# ESP32-S31 register map
Vendor: ESPRESSIF SYSTEMS (SHANGHAI) CO., LTD.; Series: ESP32 S-Series; File version: 1
CPU: RV32IMAFC r0p0, little endian, no MPU, FPU, 0 interrupt priority bits
Address unit: 32 bits
Registers are 32-bit, read-write, reset 0x0 unless marked. A register's access mark holds for its fields unless they carry their own. Offsets are from the block's base; [hi:lo] are bit positions; {n}, {i} and the like mark numbered series.

## JPEG — JPEG Codec
Base 0x20344000
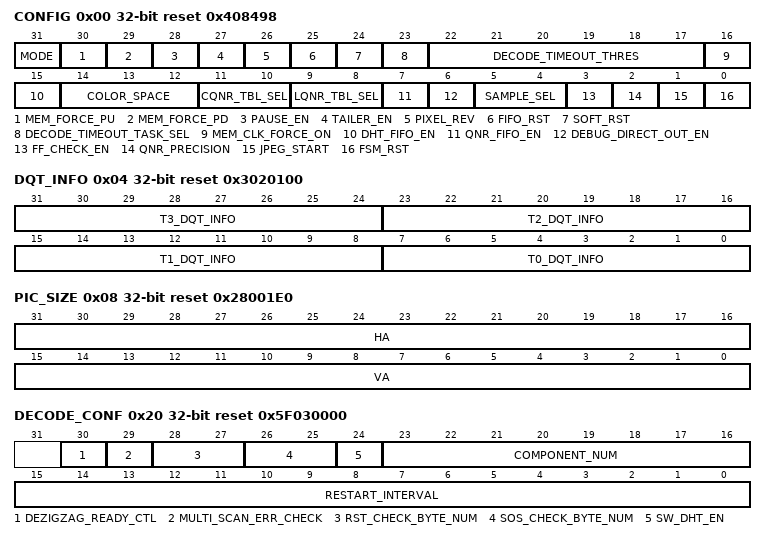
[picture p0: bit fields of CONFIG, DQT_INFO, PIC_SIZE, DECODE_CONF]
0x00 CONFIG access per field reset 0x408498 — Control and configuration registers
  [31] MODE rw — 0:encoder mode, 1: decoder mode
  [30] MEM_FORCE_PU rw — 0: no operation,1:force jpeg memory to power up
  [29] MEM_FORCE_PD rw — 0: no operation,1:force jpeg memory to power down
  [28] PAUSE_EN rw — set this bit to pause jpeg encoding
  [27] TAILER_EN rw — set this bit to add EOI of '0xffd9' at the end of bitstream
  [26] PIXEL_REV rw — reverse the source color pixel
  [25] FIFO_RST rw — fifo reset
  [24] SOFT_RST rw — when set to 1, soft reset JPEG module except jpeg_reg module
  [23] DECODE_TIMEOUT_TASK_SEL rw — 0: software use reset to abort decode process ,1: decoder abort decode process by itself
  [22:17] DECODE_TIMEOUT_THRES rw — decode pause period to trigger decode_timeout int, the timeout periods =2 power (reg_decode_timeout_thres) -1
  [16] MEM_CLK_FORCE_ON rw — force memory's clock enabled
  [15] DHT_FIFO_EN rw — 0:use non-fifo way to write dht len_total/codemin/value table,1:use fifo way to write dht len_total/codemin/value table. Reading dht len_total/codemin/value table only has nonfifo way
  [14:12] COLOR_SPACE rw — configure picture's color space:0-rgb888,1-yuv422,2-rgb565,3-gray,4-yuv444,5-yuv420
  [11:10] CQNR_TBL_SEL rw — choose chrominance quntization table id (TBD)
  [9:8] LQNR_TBL_SEL rw — choose luminance quntization table id(TBD)
  [7] QNR_FIFO_EN rw — 0:use non-fifo way to access qnr ram,1:use fifo way to access qnr ram
  [6] DEBUG_DIRECT_OUT_EN rw — 0:normal mode,1:debug mode for direct output from input
  [5:4] SAMPLE_SEL rw — 0:yuv444,1:yuv422, 2:yuv420
  [3] FF_CHECK_EN rw — enable whether to add '00' after 'ff'
  [2] QNR_PRECISION rw — 0:8bit qnr,1:12bit qnr(TBD)
  [1] JPEG_START wo — start to compress a new pic(in dma reg mode)
  [0] FSM_RST wo — fsm reset
0x04 DQT_INFO reset 0x3020100 — Control and configuration registers
  [8n+7:8n] T{n}_DQT_INFO (n=0..3) — Configure dqt table{n}'s quantization coefficient precision in bit[7:4], configure dqt table{n}'s table id in bit[3:0]
0x08 PIC_SIZE reset 0x28001E0 — Control and configuration registers
  [31:16] HA — configure picture's width. when encode, the max configurable bits is 14, when decode, the max configurable bits is 16
  [15:0] VA — configure picture's height. when encode, the max configurable bits is 14, when decode, the max configurable bits is 16
{0x10+4i} T{i}QNR ro (i=0..3) — Control and configuration registers
  [31:0] T{i}_QNR_VAL — write this reg to configure 64 quantization coefficient in t{i} table
0x20 DECODE_CONF access per field reset 0x5F030000 — Control and configuration registers
  [30] DEZIGZAG_READY_CTL rw — reserved for decoder
  [29] MULTI_SCAN_ERR_CHECK rw — reserved for decoder
  [28:27] RST_CHECK_BYTE_NUM rw — Configure the byte number to check next rst marker after one rst interval is decoded down. The real check number is reg_rst_check_byte_num+1
  [26:25] SOS_CHECK_BYTE_NUM rw — Configure the byte number to check next sos marker in the multi-scan picture after one scan is decoded down. The real check number is reg_sos_check_byte_num+1
  [24] SW_DHT_EN ro — software decode dht table enable
  [23:16] COMPONENT_NUM rw — configure number of components in frame when decode
  [15:0] RESTART_INTERVAL rw — configure restart interval in DRI marker when decode
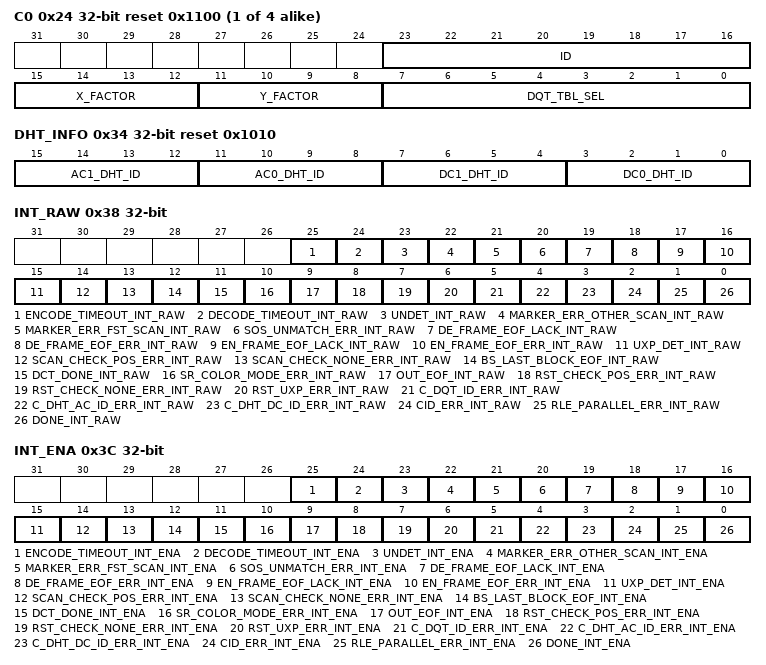
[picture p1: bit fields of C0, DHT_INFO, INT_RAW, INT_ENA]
{0x24+4i} C{i} reset 0x1100 (i=0..3) — Control and configuration registers
  [23:16] ID — the identifier of c{i}
  [15:12] X_FACTOR — horizontal sampling factor of c{i}
  [11:8] Y_FACTOR — vertical sampling factor of c{i}
  [7:0] DQT_TBL_SEL — choose c{i} quntization table id (TBD)
0x34 DHT_INFO reset 0x1010 — Control and configuration registers
  [15:12] AC1_DHT_ID — configure dht ac table 1 id
  [11:8] AC0_DHT_ID — configure dht ac table 0 id
  [7:4] DC1_DHT_ID — configure dht dc table 1 id
  [3:0] DC0_DHT_ID — configure dht dc table 0 id
0x38 INT_RAW — Interrupt raw registers
  [25] ENCODE_TIMEOUT_INT_RAW — The raw interrupt bit to sign that encode can not output bitstream time is longer than the setting encode timeout time when encoding.
  [24] DECODE_TIMEOUT_INT_RAW — The raw interrupt bit to sign that decode pause time is longer than the setting decode timeout time when decoding.
  [23] UNDET_INT_RAW — The raw interrupt bit to sign that JPEG format is not detected at the eof data of a packet when decoding.
  [22] MARKER_ERR_OTHER_SCAN_INT_RAW — The raw interrupt bit to sign that the following scans but not the first scan have header marker error when decoding.
  [21] MARKER_ERR_FST_SCAN_INT_RAW — The raw interrupt bit to sign that the first scan has header marker error when decoding.
  [20] SOS_UNMATCH_ERR_INT_RAW — The raw interrupt bit to sign that the component number of a scan is 0 or does not match the sos marker's length when decoding.
  [19] DE_FRAME_EOF_LACK_INT_RAW — The raw interrupt bit to sign that the either frame eof from dma input or eoi marker is missing when encoding. But the number of decoded blocks is enough.
  [18] DE_FRAME_EOF_ERR_INT_RAW — The raw interrupt bit to sign that decoded blocks are smaller than expected when decoding.
  [17] EN_FRAME_EOF_LACK_INT_RAW — The raw interrupt bit to sign that the frame eof sign bit from dma input is missing when encoding. But the number of pixel blocks is enough.
  [16] EN_FRAME_EOF_ERR_INT_RAW — The raw interrupt bit to sign that received pixel blocks are smaller than expected when encoding.
  [15] UXP_DET_INT_RAW — The raw interrupt bit to sign that unsupported header marker is detected when decoding.
  [14] SCAN_CHECK_POS_ERR_INT_RAW — The raw interrupt bit to sign that SOS header marker position wrong when decoding.
  [13] SCAN_CHECK_NONE_ERR_INT_RAW — The raw interrupt bit to sign that SOS header marker is not detected but there are still components left to be decoded.
  [12] BS_LAST_BLOCK_EOF_INT_RAW — The raw interrupt bit to sign that the coding process for last block is finished.
  [11] DCT_DONE_INT_RAW — The raw interrupt bit to sign that one dct calculation is finished.
  [10] SR_COLOR_MODE_ERR_INT_RAW — The raw interrupt bit to sign that the selected source color mode is not supported.
  [9] OUT_EOF_INT_RAW — The raw interrupt bit turns to high level when the last pixel of one square has been transmitted for Tx channel.
  [8] RST_CHECK_POS_ERR_INT_RAW — The raw interrupt bit to sign that RST header marker position mismatches with restart interval when decoding.
  [7] RST_CHECK_NONE_ERR_INT_RAW — The raw interrupt bit to sign that RST header marker is not detected but restart interval is not 0 when decoding.
  [6] RST_UXP_ERR_INT_RAW — The raw interrupt bit to sign that RST header marker is detected but restart interval is 0 when decoding.
  [5] C_DQT_ID_ERR_INT_RAW — The raw interrupt bit to sign that scan component's dqt id check with dqt table's id fails when decoding.
  [4] C_DHT_AC_ID_ERR_INT_RAW — The raw interrupt bit to sign that scan component's ac dht id check with ac dht table's id fails when decoding.
  [3] C_DHT_DC_ID_ERR_INT_RAW — The raw interrupt bit to sign that scan component's dc dht id check with dc dht table's id fails when decoding.
  [2] CID_ERR_INT_RAW — The raw interrupt bit to sign that scan id check with component fails when decoding.
  [1] RLE_PARALLEL_ERR_INT_RAW — The raw interrupt bit to sign that rle parallel error when decoding.
  [0] DONE_INT_RAW — This raw interrupt bit turns to high level when JPEG finishes encoding a picture..
0x3C INT_ENA — Interrupt enable registers
  [25] ENCODE_TIMEOUT_INT_ENA — The enable interrupt bit to sign that encode can not output bitstream time is longer than the setting encode timeout time when encoding.
  [24] DECODE_TIMEOUT_INT_ENA — The enable interrupt bit to sign that decode pause time is longer than the setting decode timeout time when decoding.
  [23] UNDET_INT_ENA — The enable interrupt bit to sign that JPEG format is not detected at the eof data of a packet when decoding.
  [22] MARKER_ERR_OTHER_SCAN_INT_ENA — The enable interrupt bit to sign that the following scans but not the first scan have header marker error when decoding.
  [21] MARKER_ERR_FST_SCAN_INT_ENA — The enable interrupt bit to sign that the first scan has header marker error when decoding.
  [20] SOS_UNMATCH_ERR_INT_ENA — The enable interrupt bit to sign that the component number of a scan is 0 or does not match the sos marker's length when decoding.
  [19] DE_FRAME_EOF_LACK_INT_ENA — The enable interrupt bit to sign that the either frame eof from dma input or eoi marker is missing when encoding. But the number of decoded blocks is enough.
  [18] DE_FRAME_EOF_ERR_INT_ENA — The enable interrupt bit to sign that decoded blocks are smaller than expected when decoding.
  [17] EN_FRAME_EOF_LACK_INT_ENA — The enable interrupt bit to sign that the frame eof sign bit from dma input is missing when encoding. But the number of pixel blocks is enough.
  [16] EN_FRAME_EOF_ERR_INT_ENA — The enable interrupt bit to sign that received pixel blocks are smaller than expected when encoding.
  [15] UXP_DET_INT_ENA — The enable interrupt bit to sign that unsupported header marker is detected when decoding.
  [14] SCAN_CHECK_POS_ERR_INT_ENA — The enable interrupt bit to sign that SOS header marker position wrong when decoding.
  [13] SCAN_CHECK_NONE_ERR_INT_ENA — The enable interrupt bit to sign that SOS header marker is not detected but there are still components left to be decoded.
  [12] BS_LAST_BLOCK_EOF_INT_ENA — The enable interrupt bit to sign that the coding process for last block is finished.
  [11] DCT_DONE_INT_ENA — The enable interrupt bit to sign that one dct calculation is finished.
  [10] SR_COLOR_MODE_ERR_INT_ENA — The enable interrupt bit to sign that the selected source color mode is not supported.
  [9] OUT_EOF_INT_ENA — The enable interrupt bit turns to high level when the last pixel of one square has been transmitted for Tx channel.
  [8] RST_CHECK_POS_ERR_INT_ENA — The enable interrupt bit to sign that RST header marker position mismatches with restart interval when decoding.
  [7] RST_CHECK_NONE_ERR_INT_ENA — The enable interrupt bit to sign that RST header marker is not detected but restart interval is not 0 when decoding.
  [6] RST_UXP_ERR_INT_ENA — The enable interrupt bit to sign that RST header marker is detected but restart interval is 0 when decoding.
  [5] C_DQT_ID_ERR_INT_ENA — The enable interrupt bit to sign that scan component's dqt id check with dqt table's id fails when decoding.
  [4] C_DHT_AC_ID_ERR_INT_ENA — The enable interrupt bit to sign that scan component's ac dht id check with ac dht table's id fails when decoding.
  [3] C_DHT_DC_ID_ERR_INT_ENA — The enable interrupt bit to sign that scan component's dc dht id check with dc dht table's id fails when decoding.
  [2] CID_ERR_INT_ENA — The enable interrupt bit to sign that scan id check with component fails when decoding.
  [1] RLE_PARALLEL_ERR_INT_ENA — The enable interrupt bit to sign that rle parallel error when decoding.
  [0] DONE_INT_ENA — This enable interrupt bit turns to high level when JPEG finishes encoding a picture..
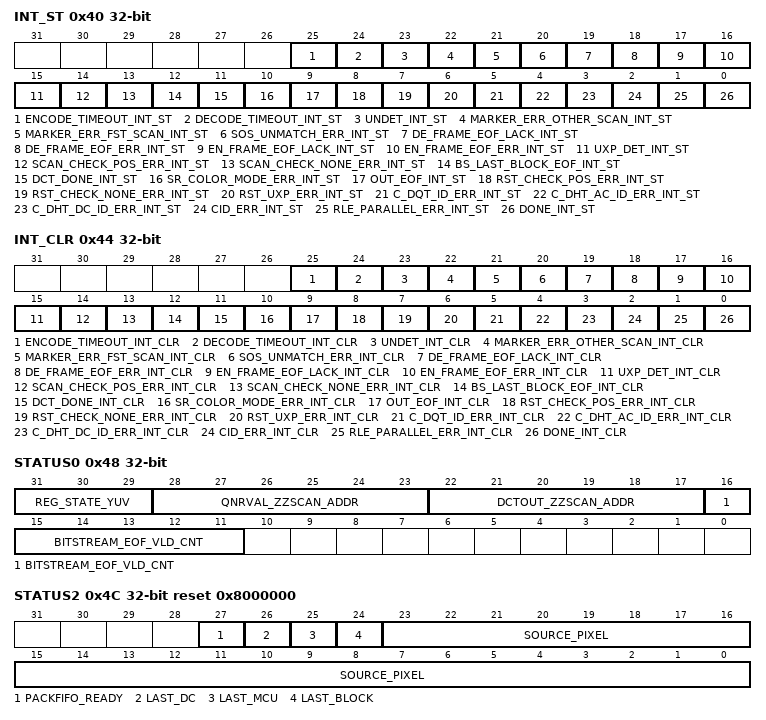
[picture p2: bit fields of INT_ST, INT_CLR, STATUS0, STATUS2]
0x40 INT_ST ro — Interrupt status registers
  [25] ENCODE_TIMEOUT_INT_ST — The status interrupt bit to sign that encode can not output bitstream time is longer than the setting encode timeout time when encoding.
  [24] DECODE_TIMEOUT_INT_ST — The status interrupt bit to sign that decode pause time is longer than the setting decode timeout time when decoding.
  [23] UNDET_INT_ST — The status interrupt bit to sign that JPEG format is not detected at the eof data of a packet when decoding.
  [22] MARKER_ERR_OTHER_SCAN_INT_ST — The status interrupt bit to sign that the following scans but not the first scan have header marker error when decoding.
  [21] MARKER_ERR_FST_SCAN_INT_ST — The status interrupt bit to sign that the first scan has header marker error when decoding.
  [20] SOS_UNMATCH_ERR_INT_ST — The status interrupt bit to sign that the component number of a scan is 0 or does not match the sos marker's length when decoding.
  [19] DE_FRAME_EOF_LACK_INT_ST — The status interrupt bit to sign that the either frame eof from dma input or eoi marker is missing when encoding. But the number of decoded blocks is enough.
  [18] DE_FRAME_EOF_ERR_INT_ST — The status interrupt bit to sign that decoded blocks are smaller than expected when decoding.
  [17] EN_FRAME_EOF_LACK_INT_ST — The status interrupt bit to sign that the frame eof sign bit from dma input is missing when encoding. But the number of pixel blocks is enough.
  [16] EN_FRAME_EOF_ERR_INT_ST — The status interrupt bit to sign that received pixel blocks are smaller than expected when encoding.
  [15] UXP_DET_INT_ST — The status interrupt bit to sign that unsupported header marker is detected when decoding.
  [14] SCAN_CHECK_POS_ERR_INT_ST — The status interrupt bit to sign that SOS header marker position wrong when decoding.
  [13] SCAN_CHECK_NONE_ERR_INT_ST — The status interrupt bit to sign that SOS header marker is not detected but there are still components left to be decoded.
  [12] BS_LAST_BLOCK_EOF_INT_ST — The status interrupt bit to sign that the coding process for last block is finished.
  [11] DCT_DONE_INT_ST — The status interrupt bit to sign that one dct calculation is finished.
  [10] SR_COLOR_MODE_ERR_INT_ST — The status interrupt bit to sign that the selected source color mode is not supported.
  [9] OUT_EOF_INT_ST — The status interrupt bit turns to high level when the last pixel of one square has been transmitted for Tx channel.
  [8] RST_CHECK_POS_ERR_INT_ST — The status interrupt bit to sign that RST header marker position mismatches with restart interval when decoding.
  [7] RST_CHECK_NONE_ERR_INT_ST — The status interrupt bit to sign that RST header marker is not detected but restart interval is not 0 when decoding.
  [6] RST_UXP_ERR_INT_ST — The status interrupt bit to sign that RST header marker is detected but restart interval is 0 when decoding.
  [5] C_DQT_ID_ERR_INT_ST — The status interrupt bit to sign that scan component's dqt id check with dqt table's id fails when decoding.
  [4] C_DHT_AC_ID_ERR_INT_ST — The status interrupt bit to sign that scan component's ac dht id check with ac dht table's id fails when decoding.
  [3] C_DHT_DC_ID_ERR_INT_ST — The status interrupt bit to sign that scan component's dc dht id check with dc dht table's id fails when decoding.
  [2] CID_ERR_INT_ST — The status interrupt bit to sign that scan id check with component fails when decoding.
  [1] RLE_PARALLEL_ERR_INT_ST — The status interrupt bit to sign that rle parallel error when decoding.
  [0] DONE_INT_ST — This status interrupt bit turns to high level when JPEG finishes encoding a picture..
0x44 INT_CLR wo — Interrupt clear registers
  [25] ENCODE_TIMEOUT_INT_CLR — The clear interrupt bit to sign that encode can not output bitstream time is longer than the setting encode timeout time when encoding.
  [24] DECODE_TIMEOUT_INT_CLR — The clear interrupt bit to sign that decode pause time is longer than the setting decode timeout time when decoding.
  [23] UNDET_INT_CLR — The clear interrupt bit to sign that JPEG format is not detected at the eof data of a packet when decoding.
  [22] MARKER_ERR_OTHER_SCAN_INT_CLR — The clear interrupt bit to sign that the following scans but not the first scan have header marker error when decoding.
  [21] MARKER_ERR_FST_SCAN_INT_CLR — The clear interrupt bit to sign that the first scan has header marker error when decoding.
  [20] SOS_UNMATCH_ERR_INT_CLR — The clear interrupt bit to sign that the component number of a scan is 0 or does not match the sos marker's length when decoding.
  [19] DE_FRAME_EOF_LACK_INT_CLR — The clear interrupt bit to sign that the either frame eof from dma input or eoi marker is missing when encoding. But the number of decoded blocks is enough.
  [18] DE_FRAME_EOF_ERR_INT_CLR — The clear interrupt bit to sign that decoded blocks are smaller than expected when decoding.
  [17] EN_FRAME_EOF_LACK_INT_CLR — The clear interrupt bit to sign that the frame eof sign bit from dma input is missing when encoding. But the number of pixel blocks is enough.
  [16] EN_FRAME_EOF_ERR_INT_CLR — The clear interrupt bit to sign that received pixel blocks are smaller than expected when encoding.
  [15] UXP_DET_INT_CLR — The clear interrupt bit to sign that unsupported header marker is detected when decoding.
  [14] SCAN_CHECK_POS_ERR_INT_CLR — The clear interrupt bit to sign that SOS header marker position wrong when decoding.
  [13] SCAN_CHECK_NONE_ERR_INT_CLR — The clear interrupt bit to sign that SOS header marker is not detected but there are still components left to be decoded.
  [12] BS_LAST_BLOCK_EOF_INT_CLR — The clear interrupt bit to sign that the coding process for last block is finished.
  [11] DCT_DONE_INT_CLR — The clear interrupt bit to sign that one dct calculation is finished.
  [10] SR_COLOR_MODE_ERR_INT_CLR — The clear interrupt bit to sign that the selected source color mode is not supported.
  [9] OUT_EOF_INT_CLR — The clear interrupt bit turns to high level when the last pixel of one square has been transmitted for Tx channel.
  [8] RST_CHECK_POS_ERR_INT_CLR — The clear interrupt bit to sign that RST header marker position mismatches with restart interval when decoding.
  [7] RST_CHECK_NONE_ERR_INT_CLR — The clear interrupt bit to sign that RST header marker is not detected but restart interval is not 0 when decoding.
  [6] RST_UXP_ERR_INT_CLR — The clear interrupt bit to sign that RST header marker is detected but restart interval is 0 when decoding.
  [5] C_DQT_ID_ERR_INT_CLR — The clear interrupt bit to sign that scan component's dqt id check with dqt table's id fails when decoding.
  [4] C_DHT_AC_ID_ERR_INT_CLR — The clear interrupt bit to sign that scan component's ac dht id check with ac dht table's id fails when decoding.
  [3] C_DHT_DC_ID_ERR_INT_CLR — The clear interrupt bit to sign that scan component's dc dht id check with dc dht table's id fails when decoding.
  [2] CID_ERR_INT_CLR — The clear interrupt bit to sign that scan id check with component fails when decoding.
  [1] RLE_PARALLEL_ERR_INT_CLR — The clear interrupt bit to sign that rle parallel error when decoding.
  [0] DONE_INT_CLR — This clear interrupt bit turns to high level when JPEG finishes encoding a picture..
0x48 STATUS0 ro — Trace and Debug registers
  [31:29] REG_STATE_YUV — the state of jpeg fsm
  [28:23] QNRVAL_ZZSCAN_ADDR — the zig-zag read addr from qnrval_ram
  [22:17] DCTOUT_ZZSCAN_ADDR — the zig-zag read addr from dctout_ram
  [16:11] BITSTREAM_EOF_VLD_CNT — the valid bit count for last bitstream
0x4C STATUS2 ro reset 0x8000000 — Trace and Debug registers
  [27] PACKFIFO_READY — the jpeg pack_fifo ready signal, high active
  [26] LAST_DC — indicate the encoding process is at the header of the last block of the picture
  [25] LAST_MCU — indicate the encoding process for the last block of the picture
  [24] LAST_BLOCK — indicate the encoding process for the last mcu of the picture
  [23:0] SOURCE_PIXEL — source pixels fetched from dma
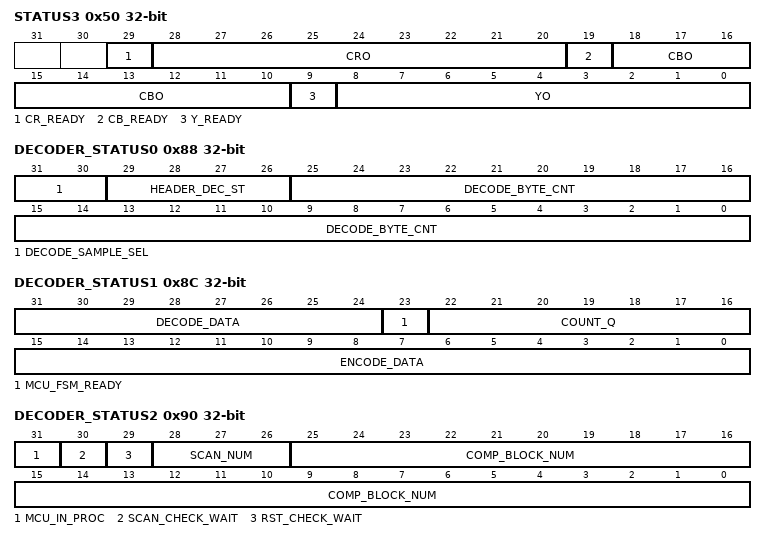
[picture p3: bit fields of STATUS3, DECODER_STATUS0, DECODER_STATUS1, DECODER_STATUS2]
0x50 STATUS3 ro — Trace and Debug registers
  [29] CR_READY — component cr valid signal, high active
  [28:20] CRO — component cr transferred from rgb input
  [19] CB_READY — component cb valid signal, high active
  [18:10] CBO — component cb transferred from rgb input
  [9] Y_READY — component y valid signal, high active
  [8:0] YO — component y transferred from rgb input
0x54 STATUS4 ro — Trace and Debug registers
  [31:0] HFM_BITSTREAM — the hufman bitstream during encoding process
0x58 DHT_TOTLEN_DC0 ro — Trace and Debug registers
  [31:0] DHT_TOTLEN_DC0 — write the numbers of 1~n codeword length sum from 1~16 of dc0 table
0x5C DHT_VAl_DC0 ro — Trace and Debug registers
  [31:0] DHT_VAL_DC0 — write codeword corresponding huffman values of dc0 table
0x60 DHT_TOTLEN_AC0 ro — Trace and Debug registers
  [31:0] DHT_TOTLEN_AC0 — write the numbers of 1~n codeword length sum from 1~16 of ac0 table
0x64 DHT_VAl_AC0 ro — Trace and Debug registers
  [31:0] DHT_VAL_AC0 — write codeword corresponding huffman values of ac0 table
0x68 DHT_TOTLEN_DC1 ro — Trace and Debug registers
  [31:0] DHT_TOTLEN_DC1 — write the numbers of 1~n codeword length sum from 1~16 of dc1 table
0x6C DHT_VAl_DC1 ro — Trace and Debug registers
  [31:0] DHT_VAL_DC1 — write codeword corresponding huffman values of dc1 table
0x70 DHT_TOTLEN_AC1 ro — Trace and Debug registers
  [31:0] DHT_TOTLEN_AC1 — write the numbers of 1~n codeword length sum from 1~16 of ac1 table
0x74 DHT_VAl_AC1 ro — Trace and Debug registers
  [31:0] DHT_VAL_AC1 — write codeword corresponding huffman values of ac1 table
0x78 DHT_CODEMIN_DC0 ro — Trace and Debug registers
  [31:0] DHT_CODEMIN_DC0 — write the minimum codeword of code length from 1~16 of dc0 table. The codeword is left shifted to the MSB position of a 16bit word
0x7C DHT_CODEMIN_AC0 ro — Trace and Debug registers
  [31:0] DHT_CODEMIN_AC0 — write the minimum codeword of code length from 1~16 of ac0 table. The codeword is left shifted to the MSB position of a 16bit word
0x80 DHT_CODEMIN_DC1 ro — Trace and Debug registers
  [31:0] DHT_CODEMIN_DC1 — write the minimum codeword of code length from 1~16 of dc1 table. The codeword is left shifted to the MSB position of a 16bit word
0x84 DHT_CODEMIN_AC1 ro — Trace and Debug registers
  [31:0] DHT_CODEMIN_AC1 — write the minimum codeword of code length from 1~16 of ac1 table. The codeword is left shifted to the MSB position of a 16bit word
0x88 DECODER_STATUS0 ro — Trace and Debug registers
  [31:30] DECODE_SAMPLE_SEL — Reserved
  [29:26] HEADER_DEC_ST — Reserved
  [25:0] DECODE_BYTE_CNT — Reserved
0x8C DECODER_STATUS1 ro — Trace and Debug registers
  [31:24] DECODE_DATA — Reserved
  [23] MCU_FSM_READY — Reserved
  [22:16] COUNT_Q — Reserved
  [15:0] ENCODE_DATA — Reserved
0x90 DECODER_STATUS2 ro — Trace and Debug registers
  [31] MCU_IN_PROC — Reserved
  [30] SCAN_CHECK_WAIT — Reserved
  [29] RST_CHECK_WAIT — Reserved
  [28:26] SCAN_NUM — Reserved
  [25:0] COMP_BLOCK_NUM — Reserved
0x94 DECODER_STATUS3 ro — Trace and Debug registers
  [31:0] LOOKUP_DATA — Reserved
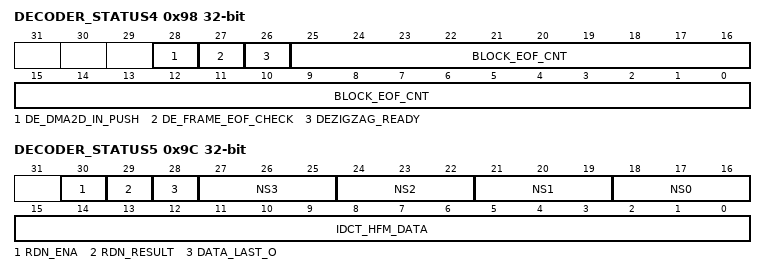
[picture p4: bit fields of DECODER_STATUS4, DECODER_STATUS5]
0x98 DECODER_STATUS4 ro — Trace and Debug registers
  [28] DE_DMA2D_IN_PUSH — Reserved
  [27] DE_FRAME_EOF_CHECK — Reserved
  [26] DEZIGZAG_READY — Reserved
  [25:0] BLOCK_EOF_CNT — Reserved
0x9C DECODER_STATUS5 access per field — Trace and Debug registers
  [30] RDN_ENA rw — redundant control registers for jpeg
  [29] RDN_RESULT ro — redundant registers for jpeg
  [28] DATA_LAST_O ro — Reserved
  [3n+18:3n+16] NS{n} ro (n=0..3) — Reserved
  [15:0] IDCT_HFM_DATA ro — Reserved
0xA0 STATUS5 ro — Trace and Debug registers
  [23:0] PIC_BLOCK_NUM — Reserved
0xA4 ECO_LOW — Trace and Debug registers
  [31:0] RDN_ECO_LOW — redundant registers for jpeg
0xA8 ECO_HIGH reset 0xFFFFFFFF — Trace and Debug registers
  [31:0] RDN_ECO_HIGH — redundant registers for jpeg
0xAC CONFIG1 reset 0x20 — Control and configuration registers
  [5:0] ENCODE_TIMEOUT_THRES — Configure the timeout period for encode can not output bitstream. The timeout periods =2 power (reg_encode_timeout_thres) -1
0xF8 SYS — Trace and Debug registers
  [31] CLK_EN — Reserved
0xFC VERSION reset 0x2503130 — Trace and Debug registers
  [27:0] JPEG_VER — Reserved
